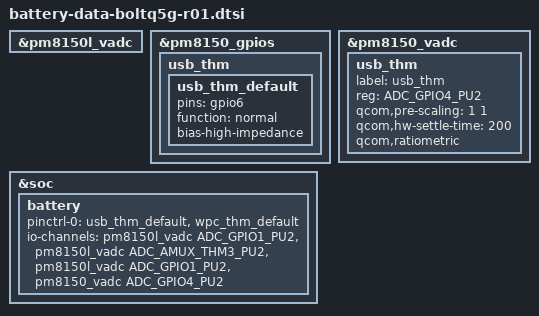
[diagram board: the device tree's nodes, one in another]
/* Copyright (c) 2014, The Linux Foundation. All rights reserved.
 *
 * This program is free software; you can redistribute it and/or modify
 * it under the terms of the GNU General Public License version 2 and
 * only version 2 as published by the Free Software Foundation.
 *
 * This program is distributed in the hope that it will be useful,
 * but WITHOUT ANY WARRANTY; without even the implied warranty of
 * MERCHANTABILITY or FITNESS FOR A PARTICULAR PURPOSE.  See the
 * GNU General Public License for more details.
 */

/* This dtsi is for hw rev 01*/
#include "battery-data-boltq5g-common.dtsi"

&pm8150l_vadc {
	/delete-node/ usb_thm;
};

&pm8150_gpios {
	usb_thm { /* GPIO_06 */
		usb_thm_default: usb_thm_default {
			pins = "gpio6";
			function = "normal";
			bias-high-impedance;
		};
	};
};

&pm8150_vadc {
	usb_thm { /* GPIO_06 */
		label = "usb_thm";
		reg = <ADC_GPIO4_PU2>;
		qcom,pre-scaling = <1 1>;
		qcom,hw-settle-time = <200>;
		qcom,ratiometric;
	};
};

&soc {
	battery {
		pinctrl-0 = <&usb_thm_default &wpc_thm_default>;
		io-channels = <&pm8150l_vadc ADC_GPIO1_PU2>, <&pm8150l_vadc ADC_AMUX_THM3_PU2>, <&pm8150l_vadc ADC_GPIO1_PU2>, <&pm8150_vadc ADC_GPIO4_PU2>;
	};
};
